AUTOSAR XML (schema 4-0-3)
standard types defined: UInt32, UInt8
package /AUTOSAR_Platform/DataConstrs
  range DC_UInt8: raw 0..255
package /PATAC/MSM/ComponentTypes
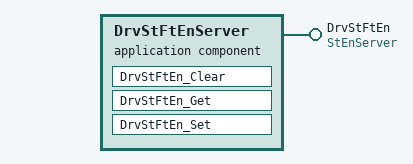
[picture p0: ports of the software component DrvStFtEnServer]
  application sw component type DrvStFtEnServer
    provide port DrvStFtEn: provided-com-specs=[{operation=Clear, queue-length=1}, {operation=Get, queue-length=1}, {operation=Set, queue-length=1}], provided-interface=StEnServer
    behavior DrvStFtEnServer_InternalBehavior
      operation invoked event OIT_DrvStFtEn_Clear_DrvStFtEn_Clear: start-on-event=DrvStFtEn_Clear, operation=DrvStFtEn.Clear
      operation invoked event OIT_DrvStFtEn_Get_DrvStFtEn_Get: start-on-event=DrvStFtEn_Get, operation=DrvStFtEn.Get
      operation invoked event OIT_DrvStFtEn_Set_DrvStFtEn_Set: start-on-event=DrvStFtEn_Set, operation=DrvStFtEn.Set
      runnable DrvStFtEn_Clear
      runnable DrvStFtEn_Get
      runnable DrvStFtEn_Set
  swc implementation DrvStFtEnServer_Implementation: behavior=DrvStFtEnServer_InternalBehavior
    code-descriptors:
      code Default: artifact-descriptors=autosar-engineering-object={short-label=Default, category=SWSRC}
package /PATAC/MSM/ModeAdjust/PortInterface
  client server interface StEnServer
    operation Clear
      arg data: type=UInt8, direction=IN, server-argument-impl-policy=USE-ARGUMENT-TYPE
    operation Get
      arg data: type=UInt32, direction=OUT, server-argument-impl-policy=USE-ARGUMENT-TYPE
    operation Set
      arg data: type=UInt8, direction=IN, server-argument-impl-policy=USE-ARGUMENT-TYPE
